# TC37XPD register map
Vendor: Infineon; Series: ATVMC; File version: 100
CPU: other r0p0, little endian, MPU, FPU, vendor SysTick, 4 interrupt priority bits
Registers are 32-bit, read-write, reset 0x0 unless marked. A register's access mark holds for its fields unless they carry their own. Offsets are from the block's base; [hi:lo] are bit positions; {n}, {i} and the like mark numbered series.

## P22 — General Purpose I O Ports and Peripheral I O Lines
Base 0xF003B600
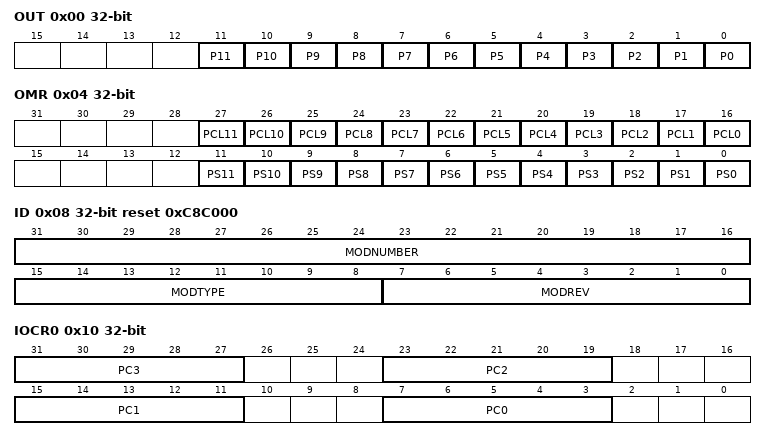
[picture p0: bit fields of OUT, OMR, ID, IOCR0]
0x00 OUT — Port 22 Output Register resetvalue={:0x0}
  [n] P{n} (n=0..11) — Output Bit 15. This bit determines the level at the output pin Pn.x if the output is selected as GPIO output. Pn.x can also be set or cleared by control bits of the Pn OMSR Pn OMCR or Pn OMR registers.
0x04 OMR wo — Port 22 Output Modification Register resetvalue={:0x0}
  [n+16] PCL{n} (n=0..11) — Clear Bit 15. Setting this bit will clear or toggle the corresponding bit in the port output register Pn OUT. Read as 0. The function of this bit is shown in Table .
  [n] PS{n} (n=0..11) — Set Bit 15. Setting this bit will set or toggle the corresponding bit in the port output register Pn OUT. Read as 0. The function of this bit is shown in Table .
0x08 ID ro reset 0xC8C000 (reset mask 0xFFFFFF00) — Port 22 Identification Register resetvalue={:0x0C8C000}
  [31:16] MODNUMBER — Module Number. This bit field defines the module identification number. The value for the Ports module is 00C8
  [15:8] MODTYPE — Module Type. This bit field is C0 H . It defines a 32 bit module
  [7:0] MODREV — Module Revision Number. This bit field indicates the revision number of the TC39x module 01 H 160 160 first revision .
0x10 IOCR0 (reset mask 0xEFEFEFEF) — Port 22 Input Output Control Register 0 resetvalue={:0x0,:0x0,:0x10101010,:0x10101010}
  [8n+7:8n+3] PC{n} (n=0..3) — Port Control for Pin 3. This bit field defines the Port n line x functionality according to Table only input selection apply.
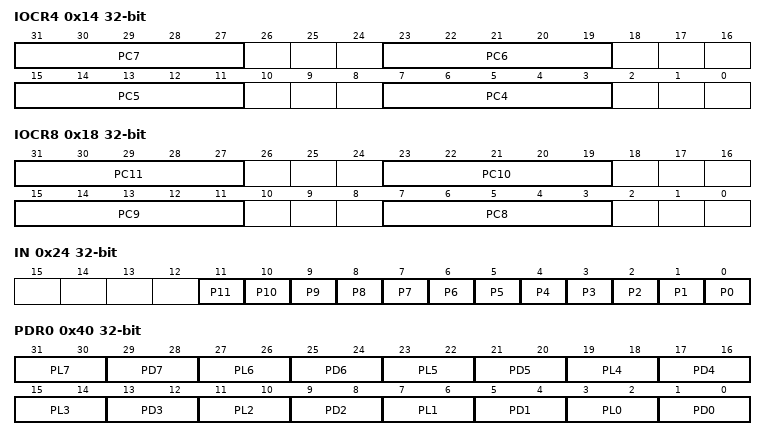
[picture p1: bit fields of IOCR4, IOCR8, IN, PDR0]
0x14 IOCR4 (reset mask 0xEFEFEFEF) — Port 22 Input Output Control Register 4 resetvalue={:0x0,:0x0,:0x10101010,:0x10101010}
  [8n-25:8n-29] PC{n} (n=4..7) — Port Control for Port 22 Pin 7. This bit field defines the Port n line x functionality according to Table only input selection apply.
0x18 IOCR8 (reset mask 0xEFEFEFEF) — Port 22 Input Output Control Register 8 resetvalue={:0x0,:0x0,:0x10101010,:0x10101010}
  [8n-57:8n-61] PC{n} (n=8..11) — Port Control for Port 22 Pin 11. This bit field defines the Port n line x functionality according to Table only input selection apply.
0x24 IN ro (reset mask 0xFFFFF000) — Port 22 Input Register resetvalue={:0x0}
  [n] P{n} (n=0..11) — Input Bit 15. This bit indicates the level at the input pin Pn.x.
0x40 PDR0 reset not defined — Port 22 Pad Driver Mode Register 0 resetvalue={:0x0,:0x0,After SSW execution:0x22222222,After SSW execution:0x22222222}
  [4n+3:4n+2] PL{n} (n=0..7) — Pad Level Selection for Pin 7
  [4n+1:4n] PD{n} (n=0..7) — Pad Driver Mode for Pin 7
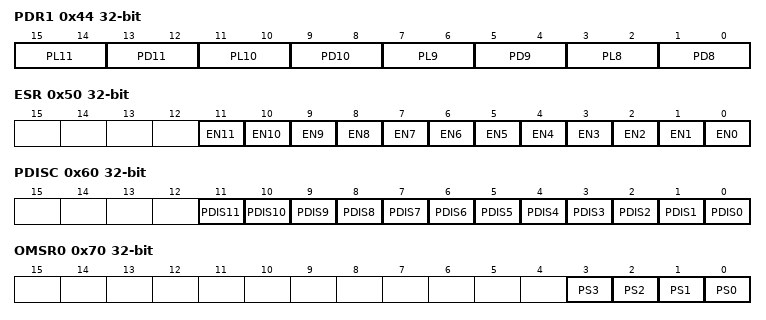
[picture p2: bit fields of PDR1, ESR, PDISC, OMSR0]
0x44 PDR1 (reset mask 0xFFFF0000) — Port 22 Pad Driver Mode Register 1 resetvalue={:0x0,:0x0,After SSW execution:0x2222,After SSW execution:0x2222}
  [4n-29:4n-30] PL{n} (n=8..11) — Pad Level Selection for Pin 15
  [4n-31:4n-32] PD{n} (n=8..11) — Pad Driver Mode for Pin 15
0x50 ESR — Port 22 Emergency Stop Register resetvalue={:0x0}
  [n] EN{n} (n=0..11) — Emergency Stop Enable for Pin 15. This bit enables the emergency stop function for all GPIO lines. If the emergency stop condition is met and enabled the output selection is automatically switched from alternate output function to GPIO input function.
0x60 PDISC (reset mask 0xFFFFF000) — Port 22 Pin Function Decision Control Register resetvalue={:0x0,:0x0,After SSW execution:0x0,After SSW execution:0x0}
  [n] PDIS{n} (n=0..11) — Pin Function Decision Control for Pin 15. This bit selects the function of the port pad.
0x70 OMSR0 wo — Port 22 Output Modification Set Register 0 resetvalue={:0x0}
  [n] PS{n} (n=0..3) — Set Bit 3. Setting this bit will set the corresponding bit in the port output register Pn OUT. Read as 0.
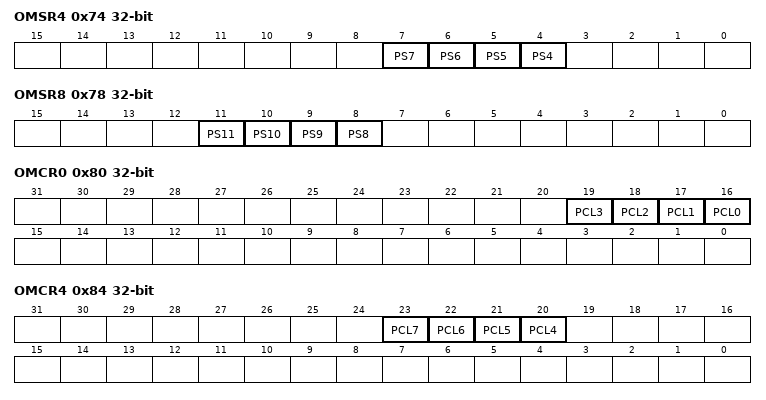
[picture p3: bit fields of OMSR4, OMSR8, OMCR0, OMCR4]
0x74 OMSR4 wo — Port 22 Output Modification Set Register 4 resetvalue={:0x0}
  [n] PS{n} (n=4..7) — Set Bit 7. Setting this bit will set the corresponding bit in the port output register Pn OUT. Read as 0.
0x78 OMSR8 wo — Port 22 Output Modification Set Register 8 resetvalue={:0x0}
  [n] PS{n} (n=8..11) — Set Bit 11. Setting this bit will set the corresponding bit in the port output register Pn OUT. Read as 0.
0x80 OMCR0 wo — Port 22 Output Modification Clear Register 0 resetvalue={:0x0}
  [n+16] PCL{n} (n=0..3) — Clear Bit 3. Setting this bit will clear the corresponding bit in the port output register Pn OUT. Read as 0.
0x84 OMCR4 wo — Port 22 Output Modification Clear Register 4 resetvalue={:0x0}
  [n+16] PCL{n} (n=4..7) — Clear Bit 7. Setting this bit will clear the corresponding bit in the port output register Pn OUT. Read as 0.
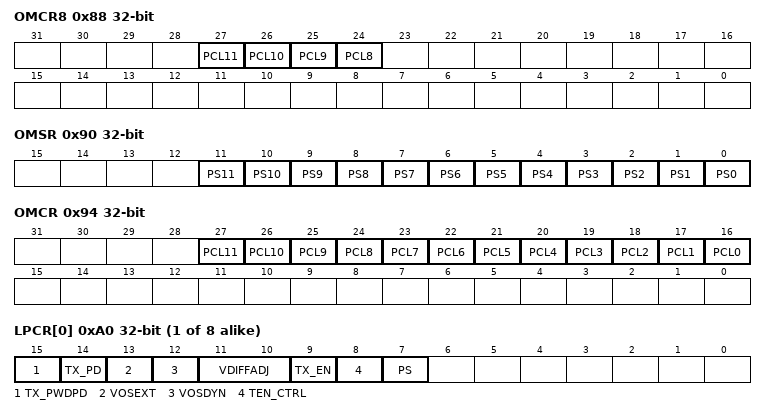
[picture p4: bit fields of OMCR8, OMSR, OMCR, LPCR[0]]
0x88 OMCR8 wo — Port 22 Output Modification Clear Register 8 resetvalue={:0x0}
  [n+16] PCL{n} (n=8..11) — Clear Bit 11. Setting this bit will clear the corresponding bit in the port output register Pn OUT. Read as 0.
0x90 OMSR wo — Port 22 Output Modification Set Register resetvalue={:0x0}
  [n] PS{n} (n=0..11) — Set Bit 15. Setting this bit will set the corresponding bit in the port output register Pn OUT. Read as 0.
0x94 OMCR wo — Port 22 Output Modification Clear Register resetvalue={:0x0}
  [n+16] PCL{n} (n=0..11) — Clear Bit 15. Setting this bit will clear the corresponding bit in the port output register Pn OUT. Read as 0.
{0xA0+4i} LPCR[{i}] (i=0..7) (reset mask 0xFFFF0000) — Port 22 LVDS Pad Control Register 0 resetvalue={:0x5480,:0x54C0,After SSW execution:0x54E0,After SSW execution:0x5480}
  [15] TX_PWDPD — Enable TX Power down pull down.. This function disables or enables the LVDS pull down resistor. The application code must disable TX power down pull down resistor with a power up. With a LVDS Power Down configuration the pull down function must be enabled if required. Driven to LVDS pad control 8220 LVDS PDN 8221 .
  [14] TX_PD — LVDS Power Down. Unused in this device. LVDS disabled by TX EN means power down. According to LVDS design spec in C40 power down means LVDSEN 0. So in C40 this bit is obsolete.
  [13] VOSEXT — Tune Bit of VOS Control Loop Internal External. Tune bit to change V OS control loop. Tune bit to change the measurement point of the V OS control loop between the actual LVDS signal on PADP PADN or the internal replica. Effective only if control loop is set to static mode with VOSDYN 0. Don 8217 t change reset value.
  [12] VOSDYN — Tune Bit of VOS Control Loop Static Dynamic. Tune bit to change V OS control loop between static and dynamic mode. Don 8217 t change reset value.
  [11:10] VDIFFADJ — LVDS Output Amplitude Tuning. With these two configuration bits the LVDS output current amplitude can be adjusted. The voltage swing depending on VDIFFADJ setting is documented in the Data Sheet see parameter V OD . Driven to LVDS pad controls LVDS VDIFF ADJ 1 0 .
  [9] TX_EN — Enable Transmit LVDS. Enable the transmit LVDS disable CMOS path. If this bit is set to 0 no transfer on LVDS data path can be initiated and the LVDS driver is disabled powered down . Driven to LVDS pad control 8220 LVDSEN 8221 .
  [8] TEN_CTRL — LVDS TX EN controller. The LVDS TX EN control function can be selected from the Port default or HSCT module where this is connected .
  [7] PS — Pad Supply Selection. Selects between 5V or 3.3V supply on V EXT for the pad pair. Used in RX and TX pads Driven to LVDS pad control 8220 LVDS 5EN 8221 . Needs also be connected to the related bias distributor.
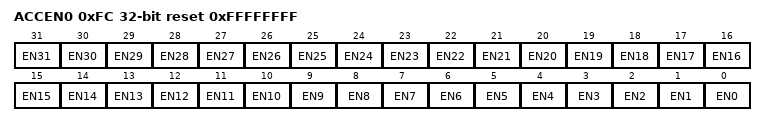
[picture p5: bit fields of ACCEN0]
0xFC ACCEN0 reset 0xFFFFFFFF — Port 22 Access Enable Register 0 resetvalue={:0x0FFFFFFFF}
  [n] EN{n} (n=0..31) — Access Enable for Master TAG ID 31. This bit enables write access to the module kernel addresses for transactions with the Master TAG ID n
